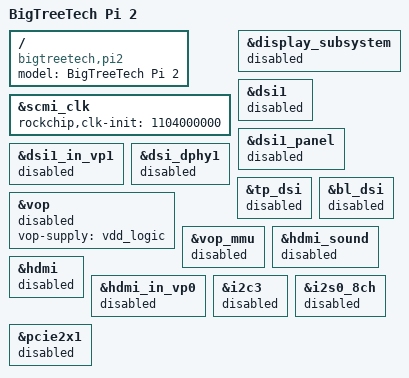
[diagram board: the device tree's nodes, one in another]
// SPDX-License-Identifier: (GPL-2.0+ OR MIT)

/dts-v1/;

#include "rk3566-bigtreetech-cb2.dtsi"

/ {
	model = "BigTreeTech Pi 2";
	compatible = "bigtreetech,pi2", "rockchip,rk3566";
};

&scmi_clk {
	rockchip,clk-init = <1104000000>;
};

/* disable all - default state */
&display_subsystem {
	status = "disabled";
};
&dsi1 {
	status = "disabled";
};
&dsi1_panel {
	status = "disabled";
};
&dsi1_in_vp1 {
	status = "disabled";
};
&dsi_dphy1 {
	status = "disabled";
};
&tp_dsi {
	status = "disabled";
};
&bl_dsi {
	status = "disabled";
};
&vop {
	vop-supply = <&vdd_logic>;
	status = "disabled";
};
&vop_mmu {
	status = "disabled";
};
&display_subsystem {
	status = "disabled";
};
&hdmi_sound {
	status = "disabled";
};
&hdmi {
	status = "disabled";
};
&hdmi_in_vp0 {
	status = "disabled";
};
&i2c3 {
	status = "disabled";
};
&i2s0_8ch {
	status = "disabled";
};
&pcie2x1 {
	status = "disabled";
};
